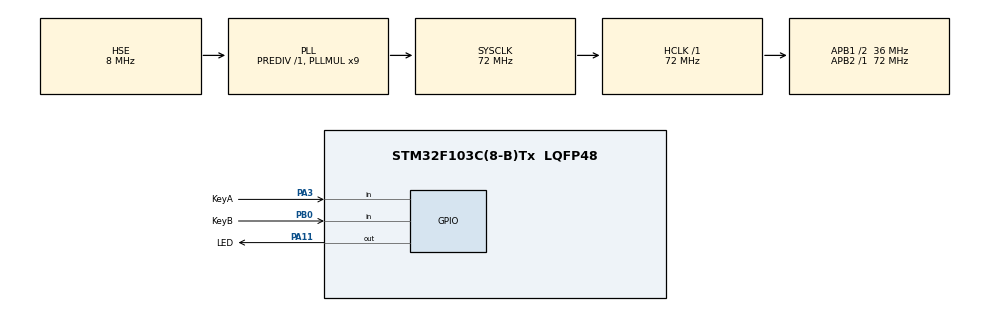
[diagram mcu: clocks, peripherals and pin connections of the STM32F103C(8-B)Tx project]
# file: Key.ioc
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Mcu.Family=STM32F1
Mcu.Name=STM32F103C(8-B)Tx
Mcu.Package=LQFP48
NVIC.PriorityGroup=NVIC_PRIORITYGROUP_4
NVIC.TIM3_IRQn=true\:0\:0\:false\:false\:true\:true\:true\:true
PA11.GPIO_Label=LED
PA11.Signal=GPIO_Output
PA13.Mode=Serial_Wire
PA13.Signal=SYS_JTMS-SWDIO
PA14.Mode=Serial_Wire
PA14.Signal=SYS_JTCK-SWCLK
PA3.GPIO_Label=KeyA
PA3.GPIO_PuPd=GPIO_PULLUP
PA3.Signal=GPIO_Input
PB0.GPIO_Label=KeyB
PB0.GPIO_PuPd=GPIO_PULLUP
PB0.Signal=GPIO_Input
PD0-OSC_IN.Mode=HSE-External-Oscillator
PD0-OSC_IN.Signal=RCC_OSC_IN
PD1-OSC_OUT.Mode=HSE-External-Oscillator
PD1-OSC_OUT.Signal=RCC_OSC_OUT
ProjectManager.HeapSize=0x200
ProjectManager.StackSize=0x400
ProjectManager.TargetToolchain=STM32CubeIDE
RCC.AHBFreq_Value=72000000
RCC.APB1CLKDivider=RCC_HCLK_DIV2
RCC.APB1Freq_Value=36000000
RCC.APB1TimFreq_Value=72000000
RCC.APB2Freq_Value=72000000
RCC.APB2TimFreq_Value=72000000
RCC.HCLKFreq_Value=72000000
RCC.PLLMUL=RCC_PLL_MUL9
RCC.PLLSourceVirtual=RCC_PLLSOURCE_HSE
RCC.SYSCLKFreq_VALUE=72000000
RCC.SYSCLKSource=RCC_SYSCLKSOURCE_PLLCLK
RCC.USBFreq_Value=72000000
TIM3.AutoReloadPreload=TIM_AUTORELOAD_PRELOAD_ENABLE
TIM3.Period=1000-1
TIM3.Prescaler=72-1
VP_TIM3_VS_ClockSourceINT.Mode=Internal
board=custom

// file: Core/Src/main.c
/* USER CODE BEGIN Header */
/**
  ******************************************************************************
  * @file           : main.c
  * @brief          : Main program body
  ******************************************************************************
  * @attention
  *
  * Copyright (c) 2025 STMicroelectronics.
  * All rights reserved.
  *
  * This software is licensed under terms that can be found in the LICENSE file
  * in the root directory of this software component.
  * If no LICENSE file comes with this software, it is provided AS-IS.
  *
  ******************************************************************************
  */
/* USER CODE END Header */
#include "main.h"

TIM_HandleTypeDef htim3;

/* USER CODE BEGIN PV */
int KeyDelay;
unsigned char KeyOldA,KeyOldB;

typedef enum {
    LED_MODE_TOGGLE,   // 模式0：按键按下时翻转 LED 状态（按一下亮，再按一下灭）
    LED_MODE_FOLLOW    // 模式1：LED 跟随按键状态（按下亮，松开灭）
} LedMode_t;

LedMode_t KeyMode = LED_MODE_TOGGLE;

/* USER CODE END PV */

void SystemClock_Config(void);
static void MX_GPIO_Init(void);
static void MX_TIM3_Init(void);

/* USER CODE BEGIN 0 */
__weak void HAL_TIM_PeriodElapsedCallback(TIM_HandleTypeDef *htim){
	if(htim==&htim3){
		KeyDelay++;//使用非阻塞的方式对按键进行消抖
	}
}

void Key_Proc(){
	if(KeyDelay<10){
		return;//当消抖未完成时 不执行函数
	}
	KeyDelay=0;
    GPIO_PinState KeyValueA = HAL_GPIO_ReadPin(KeyA_GPIO_Port, KeyA_Pin);
    GPIO_PinState KeyValueB = HAL_GPIO_ReadPin(KeyB_GPIO_Port, KeyB_Pin);
    if(KeyMode == LED_MODE_TOGGLE){//翻转模式 按下按钮时LED状态翻转
    	if(KeyOldA == GPIO_PIN_SET && KeyValueA == GPIO_PIN_RESET) {
    	        HAL_GPIO_TogglePin(LED_GPIO_Port, LED_Pin);
    	    }
    }else if(KeyMode == LED_MODE_FOLLOW){//长按模式 检测按下LED亮起 松开时LED熄灭
    	if(KeyOldA == GPIO_PIN_SET && KeyValueA == GPIO_PIN_RESET) {
    	    	HAL_GPIO_WritePin(LED_GPIO_Port, LED_Pin, GPIO_PIN_SET);
    	    }
    	else if(KeyOldA == GPIO_PIN_RESET && KeyValueA == GPIO_PIN_SET){
    			HAL_GPIO_WritePin(LED_GPIO_Port, LED_Pin, GPIO_PIN_RESET);
    		}
    }

    if(KeyOldB == GPIO_PIN_SET && KeyValueB == GPIO_PIN_RESET){
    	KeyMode ^= 1;
    }
    KeyOldB = KeyValueB;
    KeyOldA = KeyValueA;

}

/* USER CODE END 0 */

int main(void)
{

  /* MCU Configuration--------------------------------------------------------*/

  /* Reset of all peripherals, Initializes the Flash interface and the Systick. */
  HAL_Init();

  /* Configure the system clock */
  SystemClock_Config();

  /* Initialize all configured peripherals */
  MX_GPIO_Init();
  MX_TIM3_Init();
  /* USER CODE BEGIN 2 */
  HAL_TIM_Base_Start_IT(&htim3);//启动定时器
  /* USER CODE END 2 */

  /* Infinite loop */
  /* USER CODE BEGIN WHILE */
  while (1)
  {
	Key_Proc();
    /* USER CODE END WHILE */

  }
}

void SystemClock_Config(void)
{
  RCC_OscInitTypeDef RCC_OscInitStruct = {0};
  RCC_ClkInitTypeDef RCC_ClkInitStruct = {0};

  /** Initializes the RCC Oscillators according to the specified parameters
  * in the RCC_OscInitTypeDef structure.
  */
  RCC_OscInitStruct.OscillatorType = RCC_OSCILLATORTYPE_HSE;
  RCC_OscInitStruct.HSEState = RCC_HSE_ON;
  RCC_OscInitStruct.HSEPredivValue = RCC_HSE_PREDIV_DIV1;
  RCC_OscInitStruct.HSIState = RCC_HSI_ON;
  RCC_OscInitStruct.PLL.PLLState = RCC_PLL_ON;
  RCC_OscInitStruct.PLL.PLLSource = RCC_PLLSOURCE_HSE;
  RCC_OscInitStruct.PLL.PLLMUL = RCC_PLL_MUL9;
  if (HAL_RCC_OscConfig(&RCC_OscInitStruct) != HAL_OK)
  {
    Error_Handler();
  }

  /** Initializes the CPU, AHB and APB buses clocks
  */
  RCC_ClkInitStruct.ClockType = RCC_CLOCKTYPE_HCLK|RCC_CLOCKTYPE_SYSCLK
                              |RCC_CLOCKTYPE_PCLK1|RCC_CLOCKTYPE_PCLK2;
  RCC_ClkInitStruct.SYSCLKSource = RCC_SYSCLKSOURCE_PLLCLK;
  RCC_ClkInitStruct.AHBCLKDivider = RCC_SYSCLK_DIV1;
  RCC_ClkInitStruct.APB1CLKDivider = RCC_HCLK_DIV2;
  RCC_ClkInitStruct.APB2CLKDivider = RCC_HCLK_DIV1;

  if (HAL_RCC_ClockConfig(&RCC_ClkInitStruct, FLASH_LATENCY_2) != HAL_OK)
  {
    Error_Handler();
  }
}

static void MX_TIM3_Init(void)
{

  TIM_ClockConfigTypeDef sClockSourceConfig = {0};
  TIM_MasterConfigTypeDef sMasterConfig = {0};

  htim3.Instance = TIM3;
  htim3.Init.Prescaler = 72-1;
  htim3.Init.CounterMode = TIM_COUNTERMODE_UP;
  htim3.Init.Period = 1000-1;
  htim3.Init.ClockDivision = TIM_CLOCKDIVISION_DIV1;
  htim3.Init.AutoReloadPreload = TIM_AUTORELOAD_PRELOAD_ENABLE;
  if (HAL_TIM_Base_Init(&htim3) != HAL_OK)
  {
    Error_Handler();
  }
  sClockSourceConfig.ClockSource = TIM_CLOCKSOURCE_INTERNAL;
  if (HAL_TIM_ConfigClockSource(&htim3, &sClockSourceConfig) != HAL_OK)
  {
    Error_Handler();
  }
  sMasterConfig.MasterOutputTrigger = TIM_TRGO_RESET;
  sMasterConfig.MasterSlaveMode = TIM_MASTERSLAVEMODE_DISABLE;
  if (HAL_TIMEx_MasterConfigSynchronization(&htim3, &sMasterConfig) != HAL_OK)
  {
    Error_Handler();
  }

}

static void MX_GPIO_Init(void)
{
  GPIO_InitTypeDef GPIO_InitStruct = {0};

  /* GPIO Ports Clock Enable */
  __HAL_RCC_GPIOD_CLK_ENABLE();
  __HAL_RCC_GPIOA_CLK_ENABLE();
  __HAL_RCC_GPIOB_CLK_ENABLE();

  /*Configure GPIO pin Output Level */
  HAL_GPIO_WritePin(LED_GPIO_Port, LED_Pin, GPIO_PIN_RESET);

  /*Configure GPIO pin : KeyA_Pin */
  GPIO_InitStruct.Pin = KeyA_Pin;
  GPIO_InitStruct.Mode = GPIO_MODE_INPUT;
  GPIO_InitStruct.Pull = GPIO_PULLUP;
  HAL_GPIO_Init(KeyA_GPIO_Port, &GPIO_InitStruct);

  /*Configure GPIO pin : KeyB_Pin */
  GPIO_InitStruct.Pin = KeyB_Pin;
  GPIO_InitStruct.Mode = GPIO_MODE_INPUT;
  GPIO_InitStruct.Pull = GPIO_PULLUP;
  HAL_GPIO_Init(KeyB_GPIO_Port, &GPIO_InitStruct);

  /*Configure GPIO pin : LED_Pin */
  GPIO_InitStruct.Pin = LED_Pin;
  GPIO_InitStruct.Mode = GPIO_MODE_OUTPUT_PP;
  GPIO_InitStruct.Pull = GPIO_NOPULL;
  GPIO_InitStruct.Speed = GPIO_SPEED_FREQ_LOW;
  HAL_GPIO_Init(LED_GPIO_Port, &GPIO_InitStruct);

}

void Error_Handler(void)
{
  __disable_irq();
  while (1)
  {
  }
}
